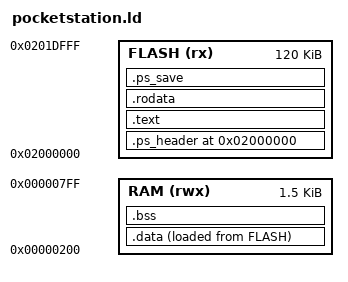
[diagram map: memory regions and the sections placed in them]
/* SPDX-License-Identifier: MIT - Copyright (c) 2026 PocketSim DevKit contributors */
/*
 * pocketstation.ld - link a PocketStation executable (MCX0 memory card file)
 *
 * The whole file is mapped by the kernel at 0x02000000, title sector first.
 * Layout:  .ps_header (title sector, PSX icon, mono icons; generated by psbuild)
 *          .text/.rodata (code runs straight from flash)
 *          .data load image
 *          .ps_save (save sectors, written at runtime with SWI 03h)
 * RAM: 0x200-0x7FF is ours (1.5 KB) for .data, .bss and the stack.
 */
OUTPUT_FORMAT("elf32-littlearm")
OUTPUT_ARCH(arm)
ENTRY(_start)

PS_STACK_SIZE = DEFINED(PS_STACK_SIZE) ? PS_STACK_SIZE : 0x200;
PS_MAX_BLOCKS = DEFINED(PS_MAX_BLOCKS) ? PS_MAX_BLOCKS : 15;

MEMORY
{
    FLASH (rx)  : ORIGIN = 0x02000000, LENGTH = 15 * 8K
    RAM   (rwx) : ORIGIN = 0x00000200, LENGTH = 0x600
}

SECTIONS
{
    .ps_header 0x02000000 :
    {
        KEEP(*(.ps_header))
        . = ALIGN(4);
    } > FLASH

    .text :
    {
        KEEP(*(.text.crt0))
        *(.text .text.* .glue_7 .glue_7t .vfp11_veneer .v4_bx)
        . = ALIGN(4);
    } > FLASH

    .rodata :
    {
        *(.rodata .rodata.*)
        . = ALIGN(4);
        __init_array_start = .;
        KEEP(*(SORT(.init_array.*)))
        KEEP(*(.init_array))
        __init_array_end = .;
        . = ALIGN(4);
    } > FLASH

    .data :
    {
        __data_start = .;
        *(.data .data.*)
        . = ALIGN(4);
        __data_end = .;
    } > RAM AT > FLASH
    __data_load = LOADADDR(.data);

    .bss (NOLOAD) :
    {
        __bss_start = .;
        *(.bss .bss.* COMMON)
        . = ALIGN(4);
        __bss_end = .;
    } > RAM

    /* save sectors: 128-byte aligned, inside the file */
    .ps_save LOADADDR(.data) + SIZEOF(.data) :
    {
        . = ALIGN(128);
        __ps_save_start = .;
        LONG(0)
        FILL(0x00000000)
        . = __ps_save_start + 512;
        __ps_save_end = .;
    } > FLASH

    __flash_end = .;
    __stack_top = 0x800;

    ASSERT(__bss_end + PS_STACK_SIZE <= __stack_top,
           "PocketStation: .data + .bss + stack exceed the 1.5 KB of user RAM")
    ASSERT(__flash_end - 0x02000000 <= PS_MAX_BLOCKS * 8192,
           "PocketStation: program is larger than the memory card blocks allowed")

    /DISCARD/ : { *(.ARM.exidx*) *(.ARM.extab*) *(.comment) *(.note*) }
}
